# PIC32MK0128MCA048 register map
Vendor: Microchip
Registers are 32-bit, read-write, reset 0x0 unless marked. A register's access mark holds for its fields unless they carry their own. Addresses are absolute, and some are shared; only a register's first bit layout is shown; [hi:lo] are bit positions; {n}, {i} and the like mark numbered series; 'fields as' and 'values as' point back to an identical list.

## ADCHS
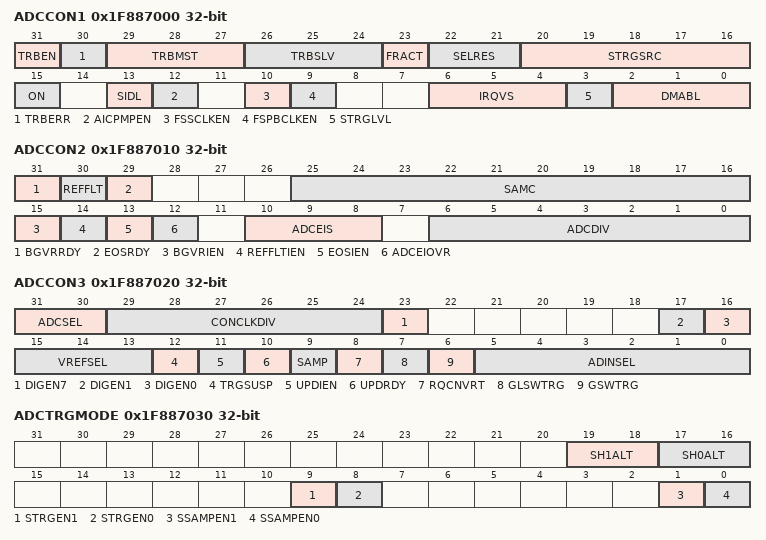
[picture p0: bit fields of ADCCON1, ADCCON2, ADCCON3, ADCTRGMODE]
0x1F887000 ADCCON1 reset not defined — (power-on value 00000110000000000-00-00--0000xxx)
  [31] TRBEN, [30] TRBERR ro, [29:27] TRBMST, [26:24] TRBSLV, [23] FRACT, [22:21] SELRES, [20:16] STRGSRC, [15] ON, [13] SIDL, [12] AICPMPEN, [10] FSSCLKEN, [9] FSPBCLKEN, [6:4] IRQVS, [3] STRGLVL, [2:0] DMABL
0x1F887010 ADCCON2
  [31] BGVRRDY ro, [30] REFFLT ro, [29] EOSRDY ro, [25:16] SAMC, [15] BGVRIEN, [14] REFFLTIEN, [13] EOSIEN, [12] ADCEIOVR, [10:8] ADCEIS, [6:0] ADCDIV
0x1F887020 ADCCON3
  [31:30] ADCSEL, [29:24] CONCLKDIV, [23] DIGEN7 ro, [17] DIGEN1 ro, [16] DIGEN0 ro, [15:13] VREFSEL, [12] TRGSUSP, [11] UPDIEN, [10] UPDRDY, [9] SAMP, [8] RQCNVRT, [7] GLSWTRG, [6] GSWTRG, [5:0] ADINSEL
0x1F887030 ADCTRGMODE
  [19:18] SH1ALT, [17:16] SH0ALT, [9] STRGEN1, [8] STRGEN0, [1] SSAMPEN1, [0] SSAMPEN0
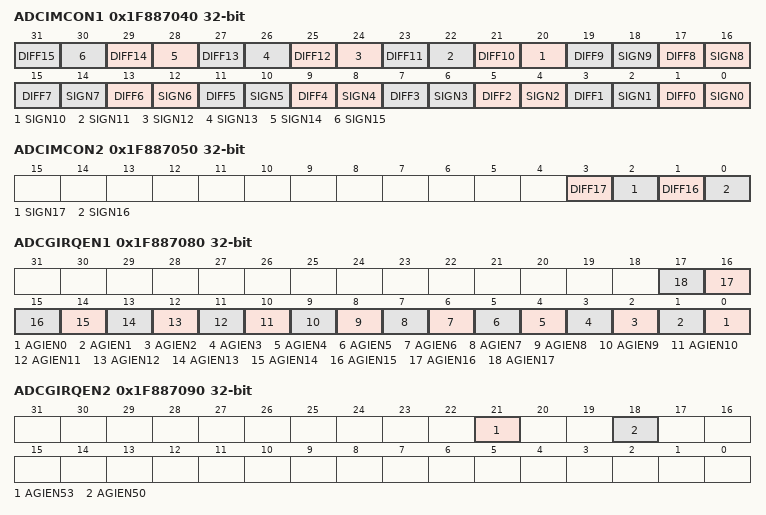
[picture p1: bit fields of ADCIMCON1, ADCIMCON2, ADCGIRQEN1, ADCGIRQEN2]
0x1F887040 ADCIMCON1
  [2n+1] DIFF{n} (n=0..15), [2n] SIGN{n} (n=0..15)
0x1F887050 ADCIMCON2
  [3] DIFF17, [2] SIGN17, [1] DIFF16, [0] SIGN16
0x1F887080 ADCGIRQEN1
  [n] AGIEN{n} (n=0..17)
0x1F887090 ADCGIRQEN2
  [21] AGIEN53, [18] AGIEN50
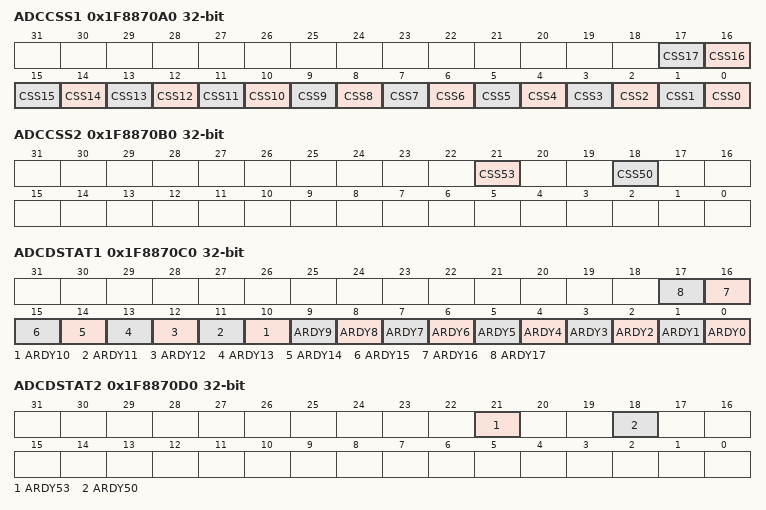
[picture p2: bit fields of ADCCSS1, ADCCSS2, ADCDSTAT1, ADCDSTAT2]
0x1F8870A0 ADCCSS1
  [n] CSS{n} (n=0..17)
0x1F8870B0 ADCCSS2
  [21] CSS53, [18] CSS50
0x1F8870C0 ADCDSTAT1 ro
  [n] ARDY{n} (n=0..17)
0x1F8870D0 ADCDSTAT2 ro
  [21] ARDY53, [18] ARDY50
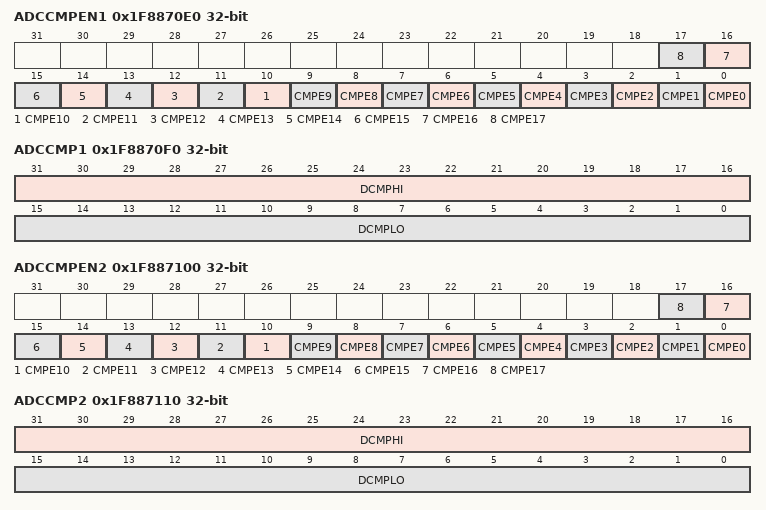
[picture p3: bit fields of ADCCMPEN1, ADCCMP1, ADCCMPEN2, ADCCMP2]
0x1F8870E0 ADCCMPEN1
  [n] CMPE{n} (n=0..17)
0x1F8870F0 ADCCMP1
  [31:16] DCMPHI, [15:0] DCMPLO
0x1F887100 ADCCMPEN2
  [n] CMPE{n} (n=0..17)
0x1F887110 ADCCMP2
  [31:16] DCMPHI, [15:0] DCMPLO
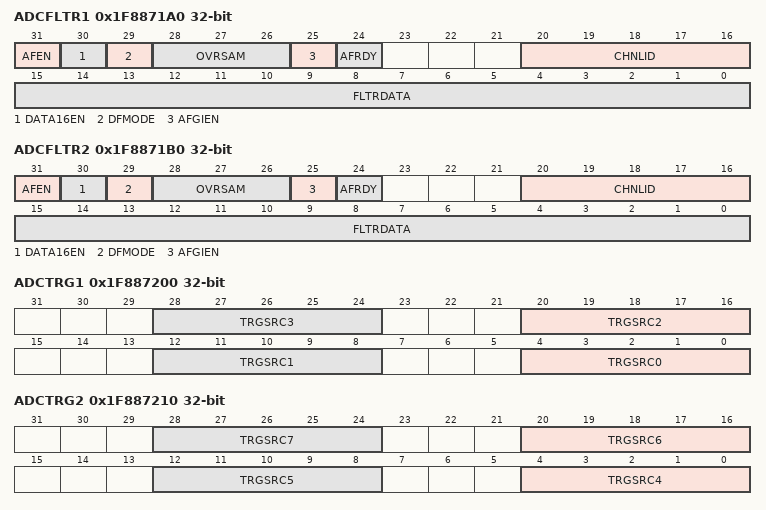
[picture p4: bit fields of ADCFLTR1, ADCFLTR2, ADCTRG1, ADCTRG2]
0x1F8871A0 ADCFLTR1
  [31] AFEN, [30] DATA16EN, [29] DFMODE, [28:26] OVRSAM, [25] AFGIEN, [24] AFRDY ro, [20:16] CHNLID, [15:0] FLTRDATA ro
0x1F8871B0 ADCFLTR2
  fields as ADCFLTR1
0x1F887200 ADCTRG1
  [8n+4:8n] TRGSRC{n} (n=0..3)
0x1F887210 ADCTRG2
  [8n-28:8n-32] TRGSRC{n} (n=4..7)
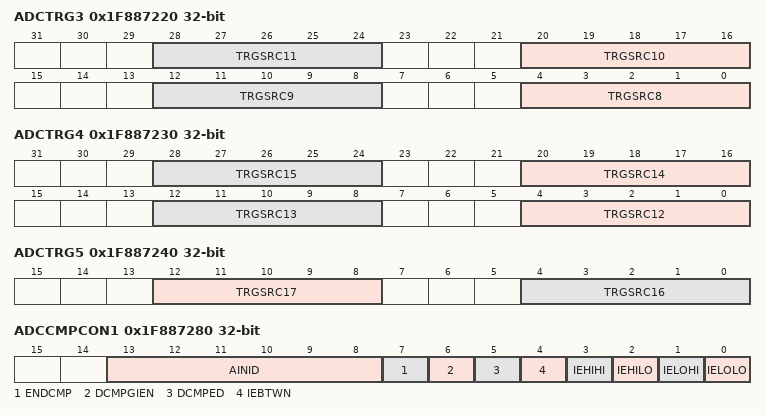
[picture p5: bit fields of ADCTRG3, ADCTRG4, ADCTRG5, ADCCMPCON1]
0x1F887220 ADCTRG3
  [8n-60:8n-64] TRGSRC{n} (n=8..11)
0x1F887230 ADCTRG4
  [8n-92:8n-96] TRGSRC{n} (n=12..15)
0x1F887240 ADCTRG5
  [12:8] TRGSRC17, [4:0] TRGSRC16
0x1F887280 ADCCMPCON1
  [13:8] AINID ro, [7] ENDCMP, [6] DCMPGIEN, [5] DCMPED ro, [4] IEBTWN, [3] IEHIHI, [2] IEHILO, [1] IELOHI, [0] IELOLO
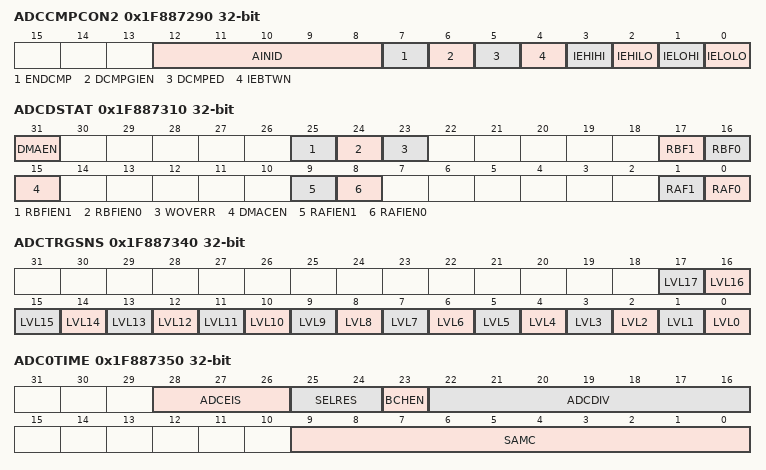
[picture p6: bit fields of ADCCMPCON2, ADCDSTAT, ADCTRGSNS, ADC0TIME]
0x1F887290 ADCCMPCON2
  [12:8] AINID ro, [7] ENDCMP, [6] DCMPGIEN, [5] DCMPED ro, [4] IEBTWN, [3] IEHIHI, [2] IEHILO, [1] IELOHI, [0] IELOLO
0x1F887300 ADCBASE
  [15:0] ADCBASE
0x1F887310 ADCDSTAT
  [31] DMAEN, [25] RBFIEN1, [24] RBFIEN0, [23] WOVERR ro, [17] RBF1 ro, [16] RBF0 ro, [15] DMACEN, [9] RAFIEN1, [8] RAFIEN0, [1] RAF1 ro, [0] RAF0 ro
0x1F887320 ADCCNTB
0x1F887330 ADCDMAB
0x1F887340 ADCTRGSNS
  [n] LVL{n} (n=0..17)
0x1F887350 ADC0TIME reset not defined — (power-on value ---00000x0000000------0000000000)
  [28:26] ADCEIS, [25:24] SELRES, [23] BCHEN, [22:16] ADCDIV, [9:0] SAMC
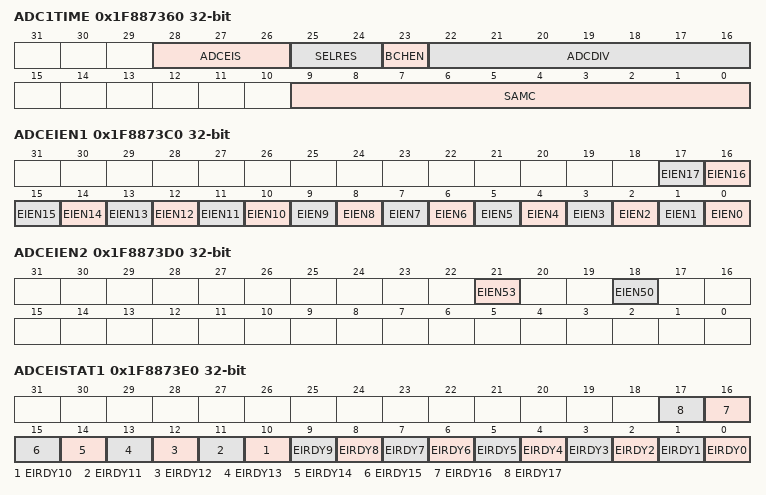
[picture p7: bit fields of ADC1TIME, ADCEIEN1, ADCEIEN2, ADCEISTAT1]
0x1F887360 ADC1TIME reset not defined — (power-on value ---00000x0000000------0000000000)
  fields as ADC0TIME
0x1F8873C0 ADCEIEN1
  [n] EIEN{n} (n=0..17)
0x1F8873D0 ADCEIEN2
  [21] EIEN53, [18] EIEN50
0x1F8873E0 ADCEISTAT1 ro
  [n] EIRDY{n} (n=0..17)
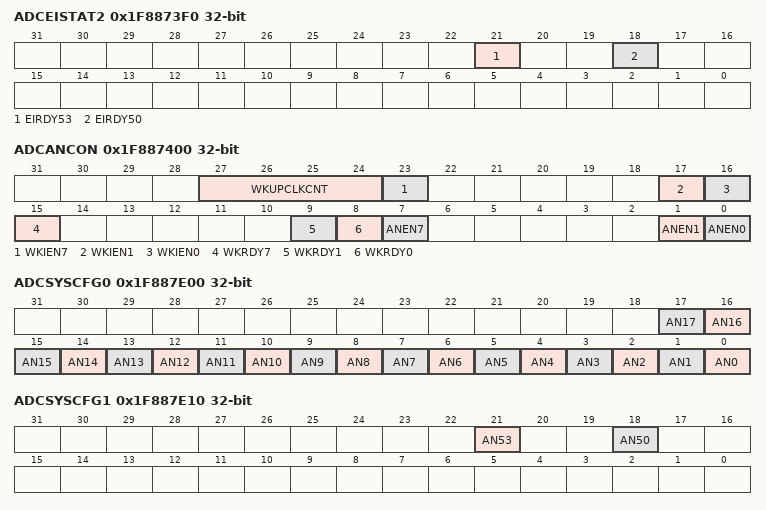
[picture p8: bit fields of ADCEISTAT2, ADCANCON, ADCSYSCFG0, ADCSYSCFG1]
0x1F8873F0 ADCEISTAT2 reset not defined — (power-on value ----------x--x------------------)
  [21] EIRDY53, [18] EIRDY50
0x1F887400 ADCANCON
  [27:24] WKUPCLKCNT, [23] WKIEN7, [17] WKIEN1, [16] WKIEN0, [15] WKRDY7 ro, [9] WKRDY1 ro, [8] WKRDY0 ro, [7] ANEN7, [1] ANEN1, [0] ANEN0
{0x1F887600+0x10*i} ADCDATA{i} (i=0..17)
  [31:0] DATA
0x1F887920 ADCDATA50
  [31:0] DATA
0x1F887950 ADCDATA53
  [31:0] DATA
0x1F887D00 ADC0CFG
  [31:0] ADCCFG
0x1F887D10 ADC1CFG
  [31:0] ADCCFG
0x1F887D70 ADC7CFG
  [31:0] ADCCFG
0x1F887E00 ADCSYSCFG0 ro
  [n] AN{n} (n=0..17)
0x1F887E10 ADCSYSCFG1 ro
  [21] AN53, [18] AN50

## RTCC
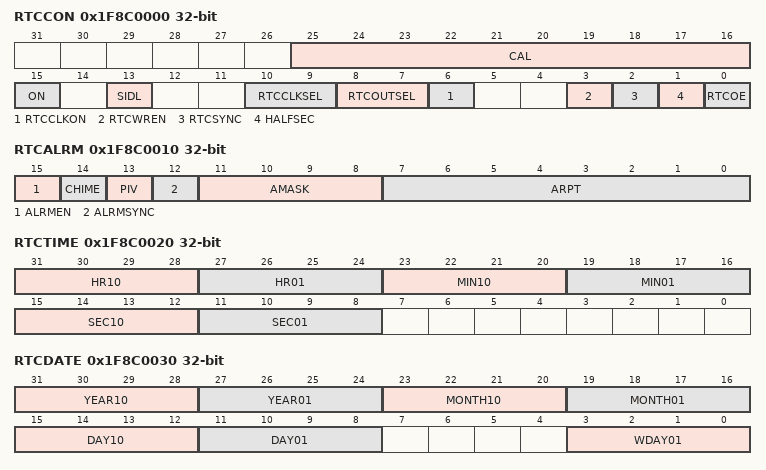
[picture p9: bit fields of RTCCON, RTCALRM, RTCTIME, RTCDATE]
0x1F8C0000 RTCCON
  [25:16] CAL, [15] ON, [13] SIDL, [10:9] RTCCLKSEL, [8:7] RTCOUTSEL, [6] RTCCLKON, [3] RTCWREN, [2] RTCSYNC ro, [1] HALFSEC ro, [0] RTCOE
0x1F8C0010 RTCALRM
  [15] ALRMEN, [14] CHIME, [13] PIV, [12] ALRMSYNC, [11:8] AMASK, [7:0] ARPT
0x1F8C0020 RTCTIME reset not defined — (power-on value 000xxxxxxxxxxxxx0xxxxxxx--------)
  [31:28] HR10, [27:24] HR01, [23:20] MIN10, [19:16] MIN01, [15:12] SEC10, [11:8] SEC01
0x1F8C0030 RTCDATE reset not defined — (power-on value xxxxxxxx000xxxxx00xxxxxx----0xxx)
  [31:28] YEAR10, [27:24] YEAR01, [23:20] MONTH10, [19:16] MONTH01, [15:12] DAY10, [11:8] DAY01, [3:0] WDAY01
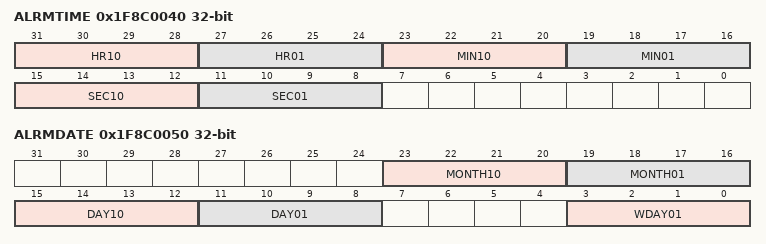
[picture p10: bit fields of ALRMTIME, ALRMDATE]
0x1F8C0040 ALRMTIME reset not defined — (power-on value 000xxxxx0xxxxxxx0xxxxxxx--------)
  fields as RTCTIME
0x1F8C0050 ALRMDATE reset not defined — (power-on value --------000xxxxx00xxxxxx----0xxx)
  [23:20] MONTH10, [19:16] MONTH01, [15:12] DAY10, [11:8] DAY01, [3:0] WDAY01

## SB
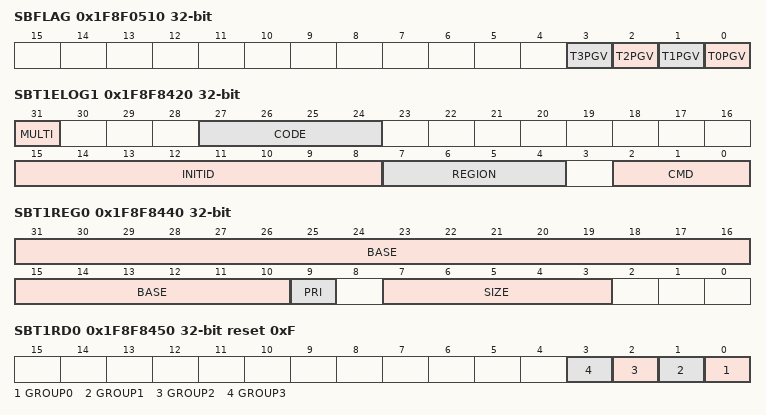
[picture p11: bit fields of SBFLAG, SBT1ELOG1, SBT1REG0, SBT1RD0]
0x1F8F0510 SBFLAG ro
  [n] T{n}PGV (n=0..3)
0x1F8F8420 SBT1ELOG1
  [31] MULTI, [27:24] CODE, [15:8] INITID ro, [7:4] REGION ro, [2:0] CMD ro
0x1F8F8424 SBT1ELOG2 ro
  [1:0] GROUP
0x1F8F8428 SBT1ECON
  [24] ERRP
0x1F8F8430 SBT1ECLRS ro
  [0] CLEAR
0x1F8F8438 SBT1ECLRM ro
  [0] CLEAR
0x1F8F8440 SBT1REG0 reset not defined — (power-on value 0000000000000000000000x-00000---)
  [31:10] BASE, [9] PRI ro, [7:3] SIZE
0x1F8F8450 SBT1RD0 reset 0xF
  [n] GROUP{n} (n=0..3)
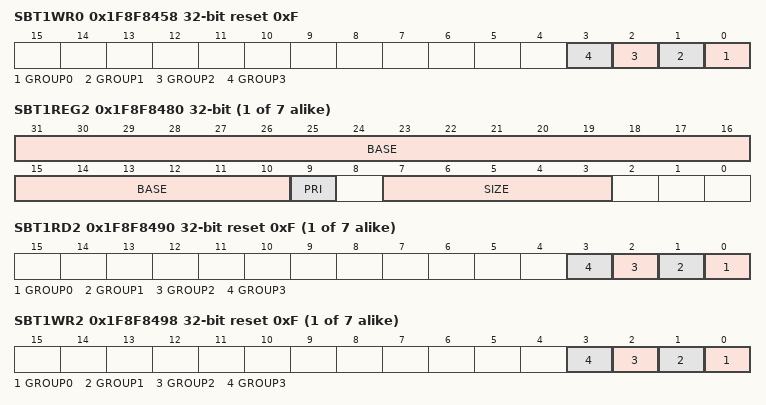
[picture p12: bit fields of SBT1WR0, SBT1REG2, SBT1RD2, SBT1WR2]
0x1F8F8458 SBT1WR0 reset 0xF
  [n] GROUP{n} (n=0..3)
{0x1F8F8440+0x20*i} SBT1REG{i} reset not defined (i=2..8) — (power-on value 0000000000000000000000x-00000---)
  [31:10] BASE, [9] PRI ro, [7:3] SIZE
{0x1F8F8450+0x20*i} SBT1RD{i} reset 0xF (i=2..8)
  [n] GROUP{n} (n=0..3)
{0x1F8F8458+0x20*i} SBT1WR{i} reset 0xF (i=2..8)
  [n] GROUP{n} (n=0..3)

## DOS_EIP_00136_ssx
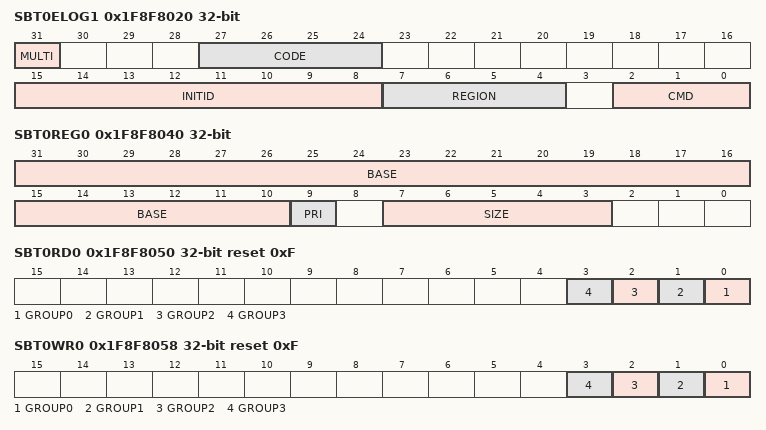
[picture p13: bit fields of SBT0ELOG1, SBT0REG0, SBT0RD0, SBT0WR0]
0x1F8F8020 SBT0ELOG1
  [31] MULTI, [27:24] CODE, [15:8] INITID ro, [7:4] REGION ro, [2:0] CMD ro
0x1F8F8024 SBT0ELOG2 ro
  [1:0] GROUP
0x1F8F8028 SBT0ECON
  [24] ERRP
0x1F8F8030 SBT0ECLRS ro
  [0] CLEAR
0x1F8F8038 SBT0ECLRM ro
  [0] CLEAR
0x1F8F8040 SBT0REG0 reset not defined — (power-on value 0000000000000000000000x-00000---)
  [31:10] BASE, [9] PRI ro, [7:3] SIZE
0x1F8F8050 SBT0RD0 reset 0xF
  [n] GROUP{n} (n=0..3)
0x1F8F8058 SBT0WR0 reset 0xF
  [n] GROUP{n} (n=0..3)
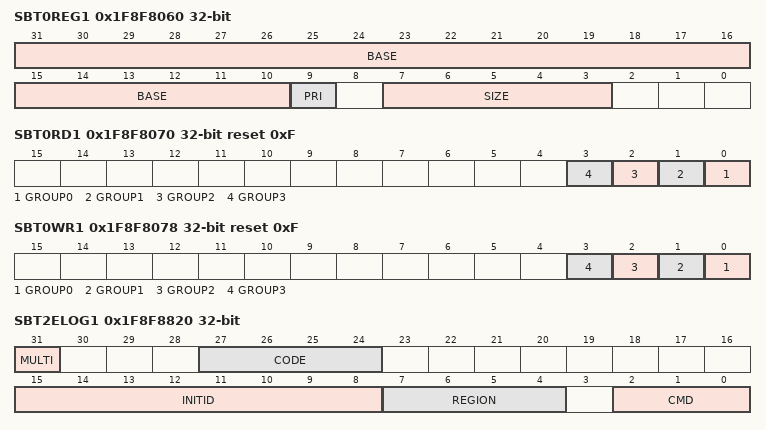
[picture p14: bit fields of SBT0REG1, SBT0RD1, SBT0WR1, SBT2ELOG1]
0x1F8F8060 SBT0REG1 reset not defined — (power-on value 0000000000000000000000x-00000---)
  [31:10] BASE, [9] PRI ro, [7:3] SIZE
0x1F8F8070 SBT0RD1 reset 0xF
  [n] GROUP{n} (n=0..3)
0x1F8F8078 SBT0WR1 reset 0xF
  [n] GROUP{n} (n=0..3)
0x1F8F8820 SBT2ELOG1
  fields as SBT0ELOG1
0x1F8F8824 SBT2ELOG2 ro
  [1:0] GROUP
0x1F8F8828 SBT2ECON
  [24] ERRP
0x1F8F8830 SBT2ECLRS ro
  [0] CLEAR
0x1F8F8838 SBT2ECLRM ro
  [0] CLEAR
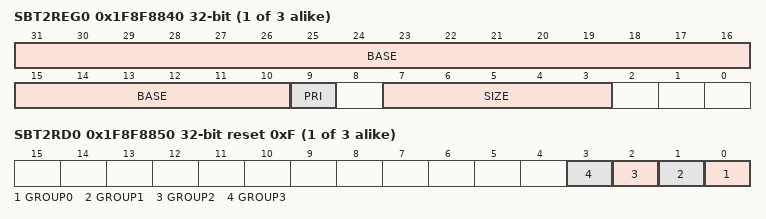
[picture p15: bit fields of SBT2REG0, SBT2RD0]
{0x1F8F8840+0x20*i} SBT2REG{i} reset not defined (i=0..2) — (power-on value 0000000000000000000000x-00000---)
  [31:10] BASE, [9] PRI ro, [7:3] SIZE
{0x1F8F8850+0x20*i} SBT2RD{i} reset 0xF (i=0..2)
  [n] GROUP{n} (n=0..3)
{0x1F8F8858+0x20*i} SBT2WR{i} reset 0xF (i=0..2)
  [n] GROUP{n} (n=0..3)
0x1F8F8C20 SBT3ELOG1
  fields as SBT0ELOG1
0x1F8F8C24 SBT3ELOG2 ro
  [1:0] GROUP
0x1F8F8C28 SBT3ECON
  [24] ERRP
0x1F8F8C30 SBT3ECLRS ro
  [0] CLEAR
0x1F8F8C38 SBT3ECLRM ro
  [0] CLEAR
{0x1F8F8C40+0x20*i} SBT3REG{i} reset not defined (i=0..2) — (power-on value 0000000000000000000000x-00000---)
  [31:10] BASE, [9] PRI ro, [7:3] SIZE
{0x1F8F8C50+0x20*i} SBT3RD{i} reset 0xF (i=0..2)
  [n] GROUP{n} (n=0..3)
{0x1F8F8C58+0x20*i} SBT3WR{i} reset 0xF (i=0..2)
  [n] GROUP{n} (n=0..3)
